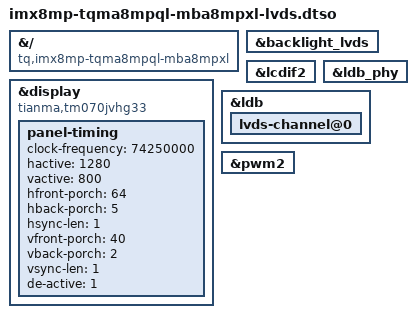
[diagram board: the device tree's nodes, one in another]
// SPDX-License-Identifier: (GPL-2.0-or-later OR MIT)
/*
 * Copyright (c) 2022 TQ-Systems GmbH <linux@ew.tq-group.com>,
 * D-82229 Seefeld, Germany.
 * Author: Alexander Stein
 */

/dts-v1/;
/plugin/;

&{/} {
	compatible = "tq,imx8mp-tqma8mpql-mba8mpxl", "tq,imx8mp-tqma8mpql", "fsl,imx8mp";
};

&backlight_lvds {
	status = "okay";
};

&display {
	compatible = "tianma,tm070jvhg33";
	status = "okay";

	panel-timing {
		clock-frequency = <74250000>;
		hactive = <1280>;
		vactive = <800>;
		hfront-porch = <64>;
		hback-porch = <5>;
		hsync-len = <1>;
		vfront-porch = <40>;
		vback-porch = <2>;
		vsync-len = <1>;
		de-active = <1>;
	};
};

&lcdif2 {
	status = "okay";
};

&ldb_phy {
	status = "okay";
};

&ldb {
	status = "okay";

	lvds-channel@0 {
		status = "okay";
	};
};

&pwm2 {
	status = "okay";
};
